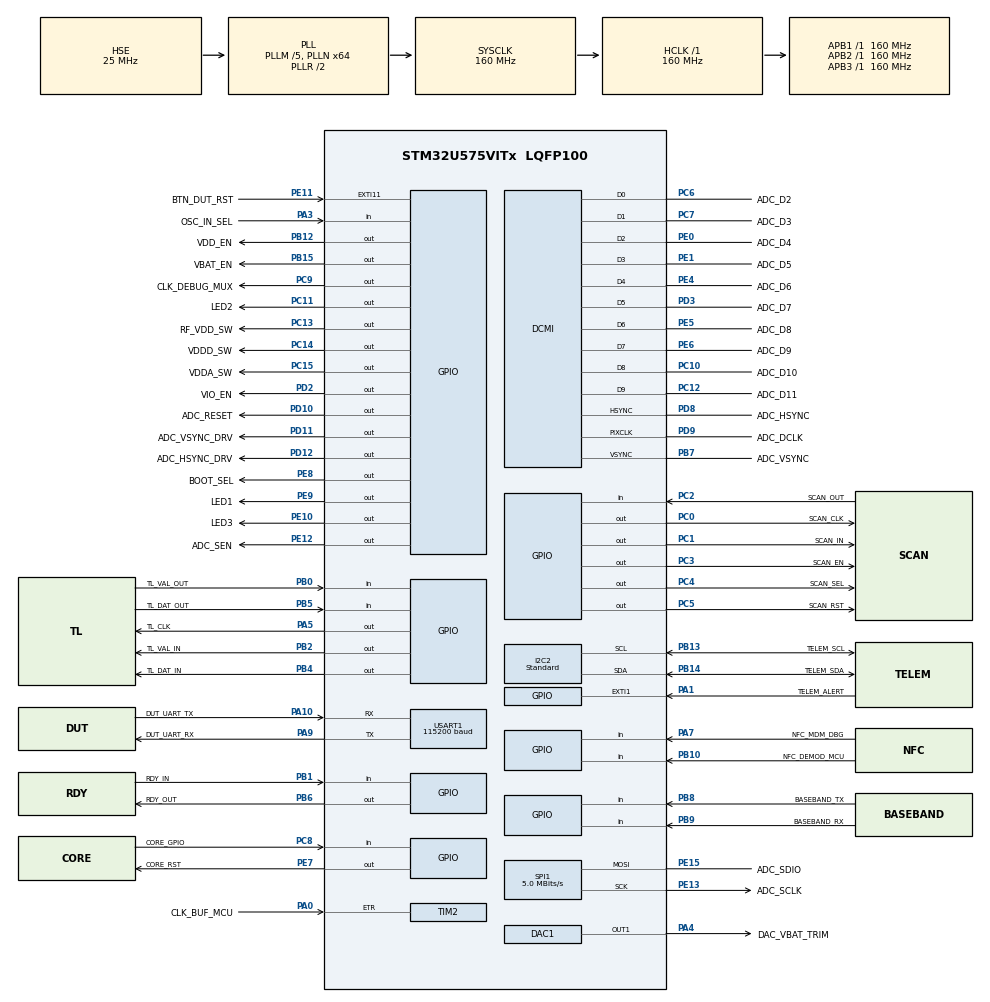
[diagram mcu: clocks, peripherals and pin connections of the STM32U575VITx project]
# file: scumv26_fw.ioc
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CORTEX_M33_NS.userName=CORTEX_M33
DAC1.DAC_Channel-DAC_OUT1=DAC_CHANNEL_1
DAC1.DAC_OutputBuffer_OUT1=DAC_OUTPUTBUFFER_ENABLE
DCMI.HSPolarity=DCMI_HSPOLARITY_HIGH
DCMI.PCKPolarity=DCMI_PCKPOLARITY_RISING
DCMI.VSPolarity=DCMI_VSPOLARITY_HIGH
I2C2.CustomTiming=Enabled
I2C2.I2C_Speed_Mode=I2C_Standard
I2C2.Speed=100
I2C2.Timing=0xF0C22731
Mcu.Family=STM32U5
Mcu.Name=STM32U575VITx
Mcu.Package=LQFP100
NVIC.EXTI11_IRQn=true\:7\:0\:false\:false\:true\:true\:true\:true
NVIC.EXTI1_IRQn=true\:1\:0\:false\:false\:true\:true\:true\:true
NVIC.PriorityGroup=NVIC_PRIORITYGROUP_4
PA0.GPIO_Label=CLK_BUF_MCU
PA0.Signal=S_TIM2_ETR
PA1.GPIO_Label=TELEM_ALERT
PA1.GPIO_ModeDefaultEXTI=GPIO_MODE_IT_FALLING
PA1.GPIO_PuPd=GPIO_PULLUP
PA1.Signal=GPXTI1
PA10.GPIO_Label=DUT_UART_TX
PA10.Mode=Asynchronous
PA10.Signal=USART1_RX
PA13\ (JTMS/SWDIO).Mode=Trace_Asynchronous_SW
PA13\ (JTMS/SWDIO).Signal=DEBUG_JTMS-SWDIO
PA14\ (JTCK/SWCLK).Mode=Trace_Asynchronous_SW
PA14\ (JTCK/SWCLK).Signal=DEBUG_JTCK-SWCLK
PA3.GPIO_Label=OSC_IN_SEL
PA3.Signal=GPIO_Input
PA4.GPIO_Label=DAC_VBAT_TRIM
PA4.Signal=COMP_DAC11_group
PA5.GPIO_Label=TL_CLK
PA5.GPIO_Speed=GPIO_SPEED_FREQ_VERY_HIGH
PA5.PinState=GPIO_PIN_RESET
PA5.Signal=GPIO_Output
PA7.GPIO_Label=NFC_MDM_DBG
PA7.Signal=GPIO_Input
PA9.GPIO_Label=DUT_UART_RX
PA9.Mode=Asynchronous
PA9.Signal=USART1_TX
PB0.GPIO_Label=TL_VAL_OUT
PB0.Signal=GPIO_Input
PB1.GPIO_Label=RDY_IN
PB1.Signal=GPIO_Input
PB10.GPIO_Label=NFC_DEMOD_MCU
PB10.Signal=GPIO_Input
PB12.GPIO_Label=VDD_EN
PB12.PinState=GPIO_PIN_RESET
PB12.Signal=GPIO_Output
PB13.GPIO_Label=TELEM_SCL
PB13.GPIO_Pu=GPIO_PULLUP
PB13.Mode=I2C
PB13.Signal=I2C2_SCL
PB14.GPIO_Label=TELEM_SDA
PB14.GPIO_Pu=GPIO_PULLUP
PB14.Mode=I2C
PB14.Signal=I2C2_SDA
PB15.GPIO_Label=VBAT_EN
PB15.PinState=GPIO_PIN_RESET
PB15.Signal=GPIO_Output
PB2.GPIO_Label=TL_VAL_IN
PB2.GPIO_Speed=GPIO_SPEED_FREQ_HIGH
PB2.PinState=GPIO_PIN_RESET
PB2.Signal=GPIO_Output
PB3\ (JTDO/TRACESWO).Mode=Trace_Asynchronous_SW
PB3\ (JTDO/TRACESWO).Signal=DEBUG_JTDO-SWO
PB4\ (NJTRST).GPIO_Label=TL_DAT_IN
PB4\ (NJTRST).GPIO_Speed=GPIO_SPEED_FREQ_HIGH
PB4\ (NJTRST).PinState=GPIO_PIN_RESET
PB4\ (NJTRST).Signal=GPIO_Output
PB5.GPIO_Label=TL_DAT_OUT
PB5.Signal=GPIO_Input
PB6.GPIO_Label=RDY_OUT
PB6.GPIO_Speed=GPIO_SPEED_FREQ_HIGH
PB6.PinState=GPIO_PIN_RESET
PB6.Signal=GPIO_Output
PB7.GPIO_Label=ADC_VSYNC
PB7.Mode=Slave_10_bits_External_Synchro
PB7.Signal=DCMI_VSYNC
PB8.GPIO_Label=BASEBAND_TX
PB8.Signal=GPIO_Input
PB9.GPIO_Label=BASEBAND_RX
PB9.Signal=GPIO_Input
PC0.GPIO_Label=SCAN_CLK
PC0.PinState=GPIO_PIN_RESET
PC0.Signal=GPIO_Output
PC1.GPIO_Label=SCAN_IN
PC1.PinState=GPIO_PIN_RESET
PC1.Signal=GPIO_Output
PC10.GPIO_Label=ADC_D10
PC10.Mode=Slave_10_bits_External_Synchro
PC10.Signal=DCMI_D8
PC11.GPIO_Label=LED2
PC11.PinState=GPIO_PIN_RESET
PC11.Signal=GPIO_Output
PC12.GPIO_Label=ADC_D11
PC12.Mode=Slave_10_bits_External_Synchro
PC12.Signal=DCMI_D9
PC13.GPIO_Label=RF_VDD_SW
PC13.PinState=GPIO_PIN_RESET
PC13.Signal=GPIO_Output
PC14-OSC32_IN\ (PC14).GPIO_Label=VDDD_SW
PC14-OSC32_IN\ (PC14).PinState=GPIO_PIN_RESET
PC14-OSC32_IN\ (PC14).Signal=GPIO_Output
PC15-OSC32_OUT\ (PC15).GPIO_Label=VDDA_SW
PC15-OSC32_OUT\ (PC15).PinState=GPIO_PIN_RESET
PC15-OSC32_OUT\ (PC15).Signal=GPIO_Output
PC2.GPIO_Label=SCAN_OUT
PC2.Signal=GPIO_Input
PC3.GPIO_Label=SCAN_EN
PC3.PinState=GPIO_PIN_RESET
PC3.Signal=GPIO_Output
PC4.GPIO_Label=SCAN_SEL
PC4.PinState=GPIO_PIN_RESET
PC4.Signal=GPIO_Output
PC5.GPIO_Label=SCAN_RST
PC5.PinState=GPIO_PIN_RESET
PC5.Signal=GPIO_Output
PC6.GPIO_Label=ADC_D2
PC6.Mode=Slave_10_bits_External_Synchro
PC6.Signal=DCMI_D0
PC7.GPIO_Label=ADC_D3
PC7.Mode=Slave_10_bits_External_Synchro
PC7.Signal=DCMI_D1
PC8.GPIO_Label=CORE_GPIO
PC8.Signal=GPIO_Input
PC9.GPIO_Label=CLK_DEBUG_MUX
PC9.PinState=GPIO_PIN_RESET
PC9.Signal=GPIO_Output
PD10.GPIO_Label=ADC_RESET
PD10.PinState=GPIO_PIN_RESET
PD10.Signal=GPIO_Output
PD11.GPIO_Label=ADC_VSYNC_DRV
PD11.GPIO_Speed=GPIO_SPEED_FREQ_HIGH
PD11.PinState=GPIO_PIN_SET
PD11.Signal=GPIO_Output
PD12.GPIO_Label=ADC_HSYNC_DRV
PD12.GPIO_Speed=GPIO_SPEED_FREQ_HIGH
PD12.PinState=GPIO_PIN_SET
PD12.Signal=GPIO_Output
PD2.GPIO_Label=VIO_EN
PD2.PinState=GPIO_PIN_RESET
PD2.Signal=GPIO_Output
PD3.GPIO_Label=ADC_D7
PD3.Mode=Slave_10_bits_External_Synchro
PD3.Signal=DCMI_D5
PD8.GPIO_Label=ADC_HSYNC
PD8.Mode=Slave_10_bits_External_Synchro
PD8.Signal=DCMI_HSYNC
PD9.GPIO_Label=ADC_DCLK
PD9.Mode=Slave_10_bits_External_Synchro
PD9.Signal=DCMI_PIXCLK
PE0.GPIO_Label=ADC_D4
PE0.Mode=Slave_10_bits_External_Synchro
PE0.Signal=DCMI_D2
PE1.GPIO_Label=ADC_D5
PE1.Mode=Slave_10_bits_External_Synchro
PE1.Signal=DCMI_D3
PE10.GPIO_Label=LED3
PE10.PinState=GPIO_PIN_RESET
PE10.Signal=GPIO_Output
PE11.GPIO_Label=BTN_DUT_RST
PE11.GPIO_ModeDefaultEXTI=GPIO_MODE_IT_FALLING
PE11.GPIO_PuPd=GPIO_PULLUP
PE11.Signal=GPXTI11
PE12.GPIO_Label=ADC_SEN
PE12.PinState=GPIO_PIN_SET
PE12.Signal=GPIO_Output
PE13.GPIO_Label=ADC_SCLK
PE13.Mode=Simplex_Bidirectional_Master
PE13.Signal=SPI1_SCK
PE15.GPIO_Label=ADC_SDIO
PE15.Mode=Simplex_Bidirectional_Master
PE15.Signal=SPI1_MOSI
PE4.GPIO_Label=ADC_D6
PE4.Mode=Slave_10_bits_External_Synchro
PE4.Signal=DCMI_D4
PE5.GPIO_Label=ADC_D8
PE5.Mode=Slave_10_bits_External_Synchro
PE5.Signal=DCMI_D6
PE6.GPIO_Label=ADC_D9
PE6.Mode=Slave_10_bits_External_Synchro
PE6.Signal=DCMI_D7
PE7.GPIO_Label=CORE_RST
PE7.PinState=GPIO_PIN_SET
PE7.Signal=GPIO_Output
PE8.GPIO_Label=BOOT_SEL
PE8.PinState=GPIO_PIN_RESET
PE8.Signal=GPIO_Output
PE9.GPIO_Label=LED1
PE9.PinState=GPIO_PIN_RESET
PE9.Signal=GPIO_Output
PH0-OSC_IN\ (PH0).Mode=HSE-External-Oscillator
PH0-OSC_IN\ (PH0).Signal=RCC_OSC_IN
PH1-OSC_OUT\ (PH1).Mode=HSE-External-Oscillator
PH1-OSC_OUT\ (PH1).Signal=RCC_OSC_OUT
PWR.PowerMode=PWR_LDO_SUPPLY
ProjectManager.HeapSize=0x200
ProjectManager.StackSize=0x1000
ProjectManager.TargetToolchain=CMake
RCC.ADCFreq_Value=16000000
RCC.AHBFreq_Value=160000000
RCC.APB1Freq_Value=160000000
RCC.APB1TimFreq_Value=160000000
RCC.APB2Freq_Value=160000000
RCC.APB2TimFreq_Value=160000000
RCC.APB3Freq_Value=160000000
RCC.CK48CLockSelection=RCC_CLK48CLKSOURCE_HSI48
RCC.CortexFreq_Value=160000000
RCC.EPOD_VALUE=25000000
RCC.HCLKFreq_Value=160000000
RCC.HSE_VALUE=25000000
RCC.HSI48_VALUE=48000000
RCC.HSI_VALUE=16000000
RCC.LSE_VALUE=32768
RCC.LSIDIV_VALUE=32000
RCC.MSI_VALUE=4000000
RCC.PLL1R=2
RCC.PLL1_VCI_Range=RCC_PLLVCIRANGE_0
RCC.PLLM=5
RCC.PLLN=64
RCC.PLLSourceVirtual=RCC_PLLSOURCE_HSE
RCC.SYSCLKFreq_VALUE=160000000
RCC.SYSCLKSource=RCC_SYSCLKSOURCE_PLLCLK
RCC.USBFreq_Value=48000000
RCC.VCOOutputFreq_Value=320000000
SH.COMP_DAC11_group.0=DAC1_OUT1,DAC_OUT1
SH.S_TIM2_ETR.0=TIM2_ETR,ClockSourceETR_Mode2
SPI1.BaudRatePrescaler=SPI_BAUDRATEPRESCALER_32
SPI1.CLKPhase=SPI_PHASE_1EDGE
SPI1.CLKPolarity=SPI_POLARITY_LOW
SPI1.CalculateBaudRate=5.0 MBits/s
SPI1.DataSize=SPI_DATASIZE_8BIT
SPI1.Direction=SPI_DIRECTION_1LINE
SPI1.FirstBit=SPI_FIRSTBIT_MSB
SPI1.Mode=SPI_MODE_MASTER
SPI1.NSS=SPI_NSS_SOFT
SPI1.VirtualType=VM_MASTER
TIM2.Prescaler=0
USART1.BaudRate=115200
USART1.VirtualMode-Asynchronous=VM_ASYNC
VP_ICACHE_VS_ICACHE.Mode=DirectMappedCache
VP_PWR_VS_DBSignals.Mode=DisableDeadBatterySignals
VP_PWR_VS_LPOM.Mode=PowerOptimisation
VP_PWR_VS_SECSignals.Mode=Security/Privilege
board=custom

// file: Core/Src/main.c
/* USER CODE BEGIN Header */
/**
  ******************************************************************************
  * @file           : main.c
  * @brief          : Main program body
  ******************************************************************************
  * @attention
  *
  * Copyright (c) 2026 STMicroelectronics.
  * All rights reserved.
  *
  * This software is licensed under terms that can be found in the LICENSE file
  * in the root directory of this software component.
  * If no LICENSE file comes with this software, it is provided AS-IS.
  *
  ******************************************************************************
  */
/* USER CODE END Header */
#include "main.h"
#include "dac.h"
#include "dcmi.h"
#include "i2c.h"
#include "icache.h"
#include "spi.h"
#include "tim.h"
#include "usart.h"
#include "gpio.h"

/* USER CODE BEGIN Includes */
#include "app.h"
/* USER CODE END Includes */

void SystemClock_Config(void);
static void SystemPower_Config(void);

int main(void)
{

  /* MCU Configuration--------------------------------------------------------*/

  /* Reset of all peripherals, Initializes the Flash interface and the Systick. */
  HAL_Init();

  /* Configure the System Power */
  SystemPower_Config();

  /* Configure the system clock */
  SystemClock_Config();

  /* Initialize all configured peripherals */
  MX_GPIO_Init();
  MX_ICACHE_Init();
  MX_DAC1_Init();
  MX_DCMI_Init();
  MX_I2C2_Init();
  MX_SPI1_Init();
  MX_TIM2_Init();
  MX_USART1_UART_Init();
  /* USER CODE BEGIN 2 */
  app_init();
  app_loop(); /* never returns */
  /* USER CODE END 2 */

  /* Infinite loop */
  while (1)
  {

  }
}

void SystemClock_Config(void)
{
  RCC_OscInitTypeDef RCC_OscInitStruct = {0};
  RCC_ClkInitTypeDef RCC_ClkInitStruct = {0};

  /** Configure the main internal regulator output voltage
  */
  if (HAL_PWREx_ControlVoltageScaling(PWR_REGULATOR_VOLTAGE_SCALE1) != HAL_OK)
  {
    Error_Handler();
  }

  /** Initializes the CPU, AHB and APB buses clocks
  */
  RCC_OscInitStruct.OscillatorType = RCC_OSCILLATORTYPE_HSI|RCC_OSCILLATORTYPE_LSI
                              |RCC_OSCILLATORTYPE_HSE;
  RCC_OscInitStruct.HSEState = RCC_HSE_ON;
  RCC_OscInitStruct.HSIState = RCC_HSI_ON;
  RCC_OscInitStruct.HSICalibrationValue = RCC_HSICALIBRATION_DEFAULT;
  RCC_OscInitStruct.LSIState = RCC_LSI_ON;
  RCC_OscInitStruct.LSIDiv = RCC_LSI_DIV1;
  RCC_OscInitStruct.PLL.PLLState = RCC_PLL_ON;
  RCC_OscInitStruct.PLL.PLLSource = RCC_PLLSOURCE_HSE;
  RCC_OscInitStruct.PLL.PLLMBOOST = RCC_PLLMBOOST_DIV2;
  RCC_OscInitStruct.PLL.PLLM = 5;
  RCC_OscInitStruct.PLL.PLLN = 64;
  RCC_OscInitStruct.PLL.PLLP = 2;
  RCC_OscInitStruct.PLL.PLLQ = 2;
  RCC_OscInitStruct.PLL.PLLR = 2;
  RCC_OscInitStruct.PLL.PLLRGE = RCC_PLLVCIRANGE_0;
  RCC_OscInitStruct.PLL.PLLFRACN = 0;
  if (HAL_RCC_OscConfig(&RCC_OscInitStruct) != HAL_OK)
  {
    Error_Handler();
  }

  /** Initializes the CPU, AHB and APB buses clocks
  */
  RCC_ClkInitStruct.ClockType = RCC_CLOCKTYPE_HCLK|RCC_CLOCKTYPE_SYSCLK
                              |RCC_CLOCKTYPE_PCLK1|RCC_CLOCKTYPE_PCLK2
                              |RCC_CLOCKTYPE_PCLK3;
  RCC_ClkInitStruct.SYSCLKSource = RCC_SYSCLKSOURCE_PLLCLK;
  RCC_ClkInitStruct.AHBCLKDivider = RCC_SYSCLK_DIV1;
  RCC_ClkInitStruct.APB1CLKDivider = RCC_HCLK_DIV1;
  RCC_ClkInitStruct.APB2CLKDivider = RCC_HCLK_DIV1;
  RCC_ClkInitStruct.APB3CLKDivider = RCC_HCLK_DIV1;

  if (HAL_RCC_ClockConfig(&RCC_ClkInitStruct, FLASH_LATENCY_4) != HAL_OK)
  {
    Error_Handler();
  }
}

/**
  * @brief Power Configuration
  * @retval None
  */
static void SystemPower_Config(void)
{

  /*
   * Disable the internal Pull-Up in Dead Battery pins of UCPD peripheral
   */
  HAL_PWREx_DisableUCPDDeadBattery();
}

void Error_Handler(void)
{
  __disable_irq();
  while (1)
  {
  }
}
